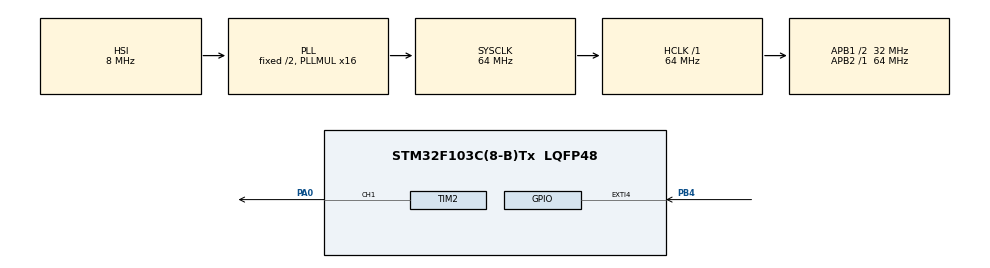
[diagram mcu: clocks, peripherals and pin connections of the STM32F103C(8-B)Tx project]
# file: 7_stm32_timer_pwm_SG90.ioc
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Mcu.Family=STM32F1
Mcu.Name=STM32F103C(8-B)Tx
Mcu.Package=LQFP48
NVIC.EXTI4_IRQn=true\:0\:0\:false\:false\:true\:true\:true\:true
NVIC.PriorityGroup=NVIC_PRIORITYGROUP_4
PA0-WKUP.Signal=S_TIM2_CH1_ETR
PA13.Mode=Serial_Wire
PA13.Signal=SYS_JTMS-SWDIO
PA14.Mode=Serial_Wire
PA14.Signal=SYS_JTCK-SWCLK
PB4.GPIO_PuPd=GPIO_PULLUP
PB4.Signal=GPXTI4
ProjectManager.HeapSize=0x200
ProjectManager.StackSize=0x400
ProjectManager.TargetToolchain=MDK-ARM V5.32
RCC.AHBFreq_Value=64000000
RCC.APB1CLKDivider=RCC_HCLK_DIV2
RCC.APB1Freq_Value=32000000
RCC.APB1TimFreq_Value=64000000
RCC.APB2Freq_Value=64000000
RCC.APB2TimFreq_Value=64000000
RCC.HCLKFreq_Value=64000000
RCC.PLLMUL=RCC_PLL_MUL16
RCC.SYSCLKFreq_VALUE=64000000
RCC.SYSCLKSource=RCC_SYSCLKSOURCE_PLLCLK
RCC.USBFreq_Value=64000000
SH.S_TIM2_CH1_ETR.0=TIM2_CH1,PWM Generation1 CH1
TIM2.Channel-PWM\ Generation1\ CH1=TIM_CHANNEL_1
TIM2.Period=19999
TIM2.Prescaler=63
VP_TIM2_VS_ClockSourceINT.Mode=Internal
board=custom

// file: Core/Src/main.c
/* USER CODE BEGIN Header */
/**
  ******************************************************************************
  * @file           : main.c
  * @brief          : Main program body
  ******************************************************************************
  * @attention
  *
  * Copyright (c) 2026 STMicroelectronics.
  * All rights reserved.
  *
  * This software is licensed under terms that can be found in the LICENSE file
  * in the root directory of this software component.
  * If no LICENSE file comes with this software, it is provided AS-IS.
  *
  ******************************************************************************
  */
/* USER CODE END Header */
#include "main.h"

TIM_HandleTypeDef htim2;

void SystemClock_Config(void);
static void MX_GPIO_Init(void);
static void MX_TIM2_Init(void);

/* USER CODE BEGIN 0 */
typedef enum {
    SG90_CW,					// clockwise
    SG90_CCW					// counter-clockwise
} SG90_Direction_t;

volatile SG90_Direction_t m_direction = SG90_CW;

void SG90_init() {
	HAL_TIM_PWM_Start(&htim2,TIM_CHANNEL_1);
}

void SG90_write(uint16_t pwm_write) {
	uint16_t _ccr = (1000*pwm_write) / 180 + 1000;
	htim2.Instance->CCR1 = _ccr;
}

// pwm_speed from 0 to 100
void SG90_write_speed(SG90_Direction_t req, uint8_t pwm_speed){
	uint16_t ccr_val = 1500;	// default
	if(req == SG90_CW) {
		ccr_val = 1500 + (pwm_speed * 5);
	} else {
		ccr_val = 1500 - (pwm_speed * 5);
	}

	htim2.Instance->CCR1 = ccr_val;
}

/* USER CODE END 0 */

int main(void)
{

  /* MCU Configuration--------------------------------------------------------*/

  /* Reset of all peripherals, Initializes the Flash interface and the Systick. */
  HAL_Init();

  /* Configure the system clock */
  SystemClock_Config();

  /* Initialize all configured peripherals */
  MX_GPIO_Init();
  MX_TIM2_Init();
  /* USER CODE BEGIN 2 */

	SG90_init();

  /* USER CODE END 2 */

  /* Infinite loop */
  while (1)
  {

    /* USER CODE BEGIN 3 */

		SG90_write_speed(m_direction, 50);
		HAL_Delay(1000);

  }
  /* USER CODE END 3 */
}

void SystemClock_Config(void)
{
  RCC_OscInitTypeDef RCC_OscInitStruct = {0};
  RCC_ClkInitTypeDef RCC_ClkInitStruct = {0};

  /** Initializes the RCC Oscillators according to the specified parameters
  * in the RCC_OscInitTypeDef structure.
  */
  RCC_OscInitStruct.OscillatorType = RCC_OSCILLATORTYPE_HSI;
  RCC_OscInitStruct.HSIState = RCC_HSI_ON;
  RCC_OscInitStruct.HSICalibrationValue = RCC_HSICALIBRATION_DEFAULT;
  RCC_OscInitStruct.PLL.PLLState = RCC_PLL_ON;
  RCC_OscInitStruct.PLL.PLLSource = RCC_PLLSOURCE_HSI_DIV2;
  RCC_OscInitStruct.PLL.PLLMUL = RCC_PLL_MUL16;
  if (HAL_RCC_OscConfig(&RCC_OscInitStruct) != HAL_OK)
  {
    Error_Handler();
  }

  /** Initializes the CPU, AHB and APB buses clocks
  */
  RCC_ClkInitStruct.ClockType = RCC_CLOCKTYPE_HCLK|RCC_CLOCKTYPE_SYSCLK
                              |RCC_CLOCKTYPE_PCLK1|RCC_CLOCKTYPE_PCLK2;
  RCC_ClkInitStruct.SYSCLKSource = RCC_SYSCLKSOURCE_PLLCLK;
  RCC_ClkInitStruct.AHBCLKDivider = RCC_SYSCLK_DIV1;
  RCC_ClkInitStruct.APB1CLKDivider = RCC_HCLK_DIV2;
  RCC_ClkInitStruct.APB2CLKDivider = RCC_HCLK_DIV1;

  if (HAL_RCC_ClockConfig(&RCC_ClkInitStruct, FLASH_LATENCY_2) != HAL_OK)
  {
    Error_Handler();
  }
}

static void MX_TIM2_Init(void)
{

  TIM_ClockConfigTypeDef sClockSourceConfig = {0};
  TIM_MasterConfigTypeDef sMasterConfig = {0};
  TIM_OC_InitTypeDef sConfigOC = {0};

  htim2.Instance = TIM2;
  htim2.Init.Prescaler = 63;
  htim2.Init.CounterMode = TIM_COUNTERMODE_UP;
  htim2.Init.Period = 19999;
  htim2.Init.ClockDivision = TIM_CLOCKDIVISION_DIV1;
  htim2.Init.AutoReloadPreload = TIM_AUTORELOAD_PRELOAD_DISABLE;
  if (HAL_TIM_Base_Init(&htim2) != HAL_OK)
  {
    Error_Handler();
  }
  sClockSourceConfig.ClockSource = TIM_CLOCKSOURCE_INTERNAL;
  if (HAL_TIM_ConfigClockSource(&htim2, &sClockSourceConfig) != HAL_OK)
  {
    Error_Handler();
  }
  if (HAL_TIM_PWM_Init(&htim2) != HAL_OK)
  {
    Error_Handler();
  }
  sMasterConfig.MasterOutputTrigger = TIM_TRGO_RESET;
  sMasterConfig.MasterSlaveMode = TIM_MASTERSLAVEMODE_DISABLE;
  if (HAL_TIMEx_MasterConfigSynchronization(&htim2, &sMasterConfig) != HAL_OK)
  {
    Error_Handler();
  }
  sConfigOC.OCMode = TIM_OCMODE_PWM1;
  sConfigOC.Pulse = 0;
  sConfigOC.OCPolarity = TIM_OCPOLARITY_HIGH;
  sConfigOC.OCFastMode = TIM_OCFAST_DISABLE;
  if (HAL_TIM_PWM_ConfigChannel(&htim2, &sConfigOC, TIM_CHANNEL_1) != HAL_OK)
  {
    Error_Handler();
  }
  HAL_TIM_MspPostInit(&htim2);

}

static void MX_GPIO_Init(void)
{
  GPIO_InitTypeDef GPIO_InitStruct = {0};

  /* GPIO Ports Clock Enable */
  __HAL_RCC_GPIOA_CLK_ENABLE();
  __HAL_RCC_GPIOB_CLK_ENABLE();

  /*Configure GPIO pin : PB4 */
  GPIO_InitStruct.Pin = GPIO_PIN_4;
  GPIO_InitStruct.Mode = GPIO_MODE_IT_RISING;
  GPIO_InitStruct.Pull = GPIO_PULLUP;
  HAL_GPIO_Init(GPIOB, &GPIO_InitStruct);

  /* EXTI interrupt init*/
  HAL_NVIC_SetPriority(EXTI4_IRQn, 0, 0);
  HAL_NVIC_EnableIRQ(EXTI4_IRQn);

}

/* USER CODE BEGIN 4 */
void HAL_GPIO_EXTI_Callback(uint16_t GPIO_Pin) {
	if(GPIO_Pin == GPIO_PIN_4) {
		m_direction = 1 - m_direction;
	}
}
/* USER CODE END 4 */

void Error_Handler(void)
{
  __disable_irq();
  while (1)
  {
  }
}
